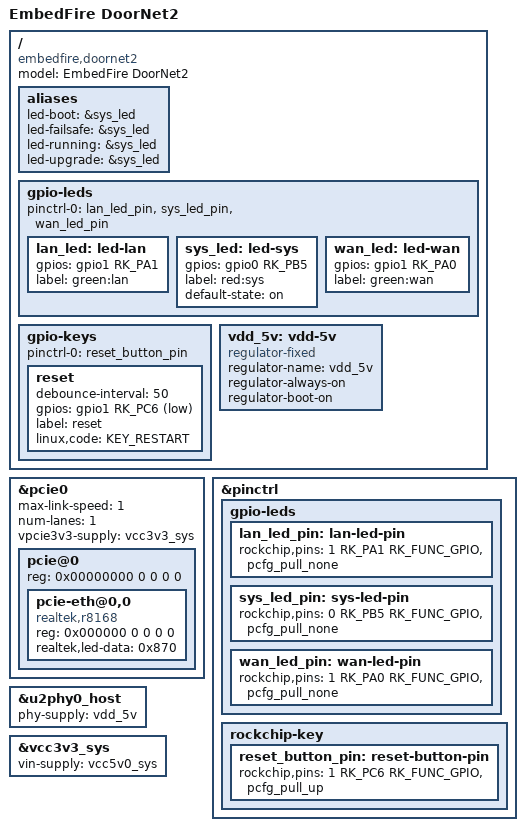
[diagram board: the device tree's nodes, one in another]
// SPDX-License-Identifier: (GPL-2.0+ OR MIT)

/dts-v1/;
#include "rk3399-doornet2.dtsi"

/ {
	model = "EmbedFire DoorNet2";
	compatible = "embedfire,doornet2", "rockchip,rk3399";

	aliases {
		led-boot = &sys_led;
		led-failsafe = &sys_led;
		led-running = &sys_led;
		led-upgrade = &sys_led;
	};

	/delete-node/ display-subsystem;

	gpio-leds {
		pinctrl-0 = <&lan_led_pin>, <&sys_led_pin>, <&wan_led_pin>;

		/delete-node/ status;

		lan_led: led-lan {
			gpios = <&gpio1 RK_PA1 GPIO_ACTIVE_HIGH>;
			label = "green:lan";
		};

		sys_led: led-sys {
			gpios = <&gpio0 RK_PB5 GPIO_ACTIVE_HIGH>;
			label = "red:sys";
			default-state = "on";
		};

		wan_led: led-wan {
			gpios = <&gpio1 RK_PA0 GPIO_ACTIVE_HIGH>;
			label = "green:wan";
		};
	};

	gpio-keys {
		pinctrl-0 = <&reset_button_pin>;

		/delete-node/ power;

		reset {
			debounce-interval = <50>;
			gpios = <&gpio1 RK_PC6 GPIO_ACTIVE_LOW>;
			label = "reset";
			linux,code = <KEY_RESTART>;
		};
	};

	vdd_5v: vdd-5v {
		compatible = "regulator-fixed";
		regulator-name = "vdd_5v";
		regulator-always-on;
		regulator-boot-on;
	};
};

&pcie0 {
	max-link-speed = <1>;
	num-lanes = <1>;
	vpcie3v3-supply = <&vcc3v3_sys>;

	pcie@0 {
		reg = <0x00000000 0 0 0 0>;
		#address-cells = <3>;
		#size-cells = <2>;

		pcie-eth@0,0 {
			compatible = "realtek,r8168";
			reg = <0x000000 0 0 0 0>;

			realtek,led-data = <0x870>;
		};
	};
};

&pinctrl {
	gpio-leds {
		/delete-node/ leds-gpio;

		lan_led_pin: lan-led-pin {
			rockchip,pins = <1 RK_PA1 RK_FUNC_GPIO &pcfg_pull_none>;
		};

		sys_led_pin: sys-led-pin {
			rockchip,pins = <0 RK_PB5 RK_FUNC_GPIO &pcfg_pull_none>;
		};

		wan_led_pin: wan-led-pin {
			rockchip,pins = <1 RK_PA0 RK_FUNC_GPIO &pcfg_pull_none>;
		};
	};

	rockchip-key {
		/delete-node/ power-key;

		reset_button_pin: reset-button-pin {
			rockchip,pins = <1 RK_PC6 RK_FUNC_GPIO &pcfg_pull_up>;
		};
	};
};

&u2phy0_host {
	phy-supply = <&vdd_5v>;
};

&vcc3v3_sys {
	vin-supply = <&vcc5v0_sys>;
};
